# H6 register map
Vendor: Allwinner; Series: H6; File version: 0.1
CPU: CA53 0, little endian, MPU, no FPU, 0 interrupt priority bits
Registers are 32-bit, read-write, reset 0x0 unless marked. A register's access mark holds for its fields unless they carry their own. Offsets are from the block's base; [hi:lo] are bit positions; {n}, {i} and the like mark numbered series; 'fields as' and 'values as' point back to an identical list; <NAME> marks a mode.

## I2S/PCM0
Base 0x05090000
Same registers: I2S/PCM3(used_for_Audio_Codec) 0x0508F000, I2S/PCM1(used_for_HDMI) 0x05091000, I2S/PCM2 0x05092000
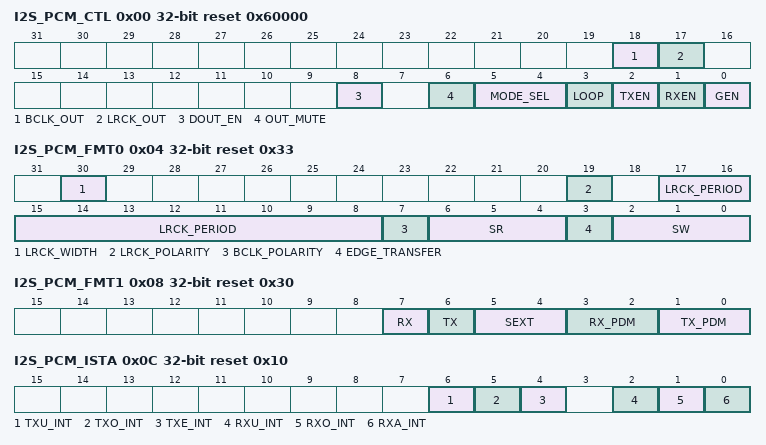
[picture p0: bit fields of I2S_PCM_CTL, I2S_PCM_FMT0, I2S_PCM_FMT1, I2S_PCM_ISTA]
0x00 I2S_PCM_CTL reset 0x60000
  [18] BCLK_OUT — 0: Input 1: Output
    0=Input; 1=Output
  [17] LRCK_OUT — 0: Input 1: Output
    0=Input; 1=Output
  [8] DOUT_EN — 0: Disable, Hi-Z State 1: Enable
    0=Disable, Hi-Z State; 1=Enable
  [6] OUT_MUTE — 0: Normal Transfer 1: Force DOUT to Output 0
    0=Normal Transfer; 1=Force DOUT to Output 0
  [5:4] MODE_SEL — Mode Selection 00: PCM Mode (offset 0: Long Frame; offset 1: Short Frame) 01: Left Mode (offset 0: LJ Mode; offset 1: I2S Mode) 10: Right-Justified Mode 11: Reserved
    0=PCM (PCM Mode (offset 0: Long Frame; offset 1: Short Frame)); 1=Left Mode (offset 0: LJ Mode; offset 1: I2S Mode); 2=Right-Justified Mode
  [3] LOOP — Loop Back Test 0: Normal Mode 1: Loop Back Test When Set `1` , Connecting the DOUT with the DIN.
    0=Normal Mode; 1=Loop Back Test When Set `1` , Connecting the DOUT with the DIN
  [2] TXEN — Transmitter Block Enable 0: Disable 1: Enable
    0=Disable; 1=Enable
  [1] RXEN — Receiver Block Enable 0: Disable 1: Enable
    0=Disable; 1=Enable
  [0] GEN — Globe Enable A disable on this bit overrides any other block or channel enables. 0: Disable 1: Enable
    0=Disable; 1=Enable
0x04 I2S_PCM_FMT0 reset 0x33
  [30] LRCK_WIDTH — (Only Apply in PCM Mode ) LRCK Width 0: LRCK = 1 BCLK Width (Short Frame) 1: LRCK = 2 BCLK Width (Long Frame)
    0=LRCK__equals__1 (LRCK = 1 BCLK Width (Short Frame)); 1=LRCK__equals__2 (LRCK = 2 BCLK Width (Long Frame))
  [19] LRCK_POLARITY — When Apply in I2S / Left-Justified / Right-Justified Mode: 0: Left Channel When LRCK is Low 1: Left Channel When LRCK is High When Apply in PCM Mode: 0: PCM LRCK Asserted at the Negative Edge 1: PCM LRCK Asserted at the Positive Edge
    0=Low (Left Channel When LRCK is Low); 1=High (Left Channel When LRCK is High When Apply in PCM Mode:); 0=PCM LRCK Asserted at the Negative Edge; 1=PCM LRCK Asserted at the Positive Edge
  [17:8] LRCK_PERIOD — It is used to program the number of BCLKs per channel of sample frame. This value is interpreted as follow: PCM Mode: Number of BCLKs within (Left + Right) channel width. I2S / Left-Justified / Right-Justified Mode: Number of BCLKs within each individual channel width (Left or Right) . N+1 For example: N = 7: 8 BCLKs width ... N = 1023: 1024 BCLKs width
  [7] BCLK_POLARITY — 0: Normal Mode, DOUT Drive Data at Negative Edge 1: Invert Mode, DOUT Drive Data at Positive Edge
    0=Normal Mode, DOUT Drive Data at Negative Edge; 1=Invert Mode, DOUT Drive Data at Positive Edge
  [6:4] SR — Sample Resolution 000: Reserved 001: 8-bit 010: 12-bit 011: 16-bit 100: 20-bit 101: 24-bit 110: 28-bit 111: 32-bit
    1=_8_bit; 2=_12_bit; 3=_16_bit; 4=_20_bit; 5=_24_bit; 6=_28_bit; 7=_32_bit
  [3] EDGE_TRANSFER — 0: DOUT Drive Data and DIN Sample Data at the Different BCLK Edge 1: DOUT Drive Data and DIN Sample Data at the Same BCLK Edge BCLK_POLARITY = 0, EDGE_TRANSFER = 0, DIN Sample Data at Positive Edge; BCLK_POLARITY = 0, EDGE_TRANSFER = 1, DIN Sample Data at Negative Edge; BCLK_POLARITY = 1, EDGE_TRANSFER = 0, DIN Sample Data at Negative Edge; BCLK_POLARITY = 1, EDGE_TRANSFER = 1, DIN Sample Data at Positive Edge.
    0=DOUT Drive Data and DIN Sample Data at the Different BCLK Edge; 1=DOUT Drive Data and DIN Sample Data at the Same BCLK Edge BCLK_POLARITY = 0, EDGE_TRANSFER = 0, DIN Sample Data at Positive Edge; BCLK_POLARITY = 0, EDGE_TRANSFER = 1, DIN Sample Data at Negative Edge; BCLK_POLARITY = 1, EDGE_TRANSFER = 0, DIN Sample Data at Negative Edge; BCLK_POLARITY = 1, EDGE_TRANSFER = 1, DIN Sample Data at Positive Edge
  [2:0] SW — Slot Width Select 000: Reserved 001: 8-bit 010: 12-bit 011: 16-bit 100: 20-bit 101: 24-bit 110: 28-bit 111: 32-bit
    values as SR
0x08 I2S_PCM_FMT1 reset 0x30
  [7] RX — MLS MSB/LSB First Select 0: MSB First 1: LSB First
    0=MSB (MSB First); 1=LSB (LSB First)
  [6] TX — MLS MSB/LSB First Select 0: MSB First 1: LSB First
    0=MSB (MSB First); 1=LSB (LSB First)
  [5:4] SEXT — Sign Extend in Slot [Sample Resolution < Slot Width] 00: Zeros or Audio Gain Padding at LSB Position 01: Sign Extension at MSB Position 10: Reserved 11: Transfer 0 after each Sample in each Slot
    0=Zeros or Audio Gain Padding at LSB Position; 1=Sign Extension at MSB Position; 3=Transfer 0 after each Sample in each Slot
  [3:2] RX_PDM — PCM Data Mode 00: Linear PCM 01: Reserved 10: 8-bit u-law 11: 8-bit A-law
    0=Linear_PCM; 2=_8_bit_ulaw; 3=_8_bit_Alaw
  [1:0] TX_PDM — PCM Data Mode 00: Linear PCM 01: Reserved 10: 8-bits u-law 11: 8-bits A-law
    0=Linear_PCM; 2=_8_bits_ulaw; 3=_8_bits_Alaw
0x0C I2S_PCM_ISTA reset 0x10
  [6] TXU_INT write-1-clears — TXFIFO Underrun Pending Interrupt 0: No Pending Interrupt 1: TXFIFO Underrun Pending Interrupt Write `1` to clear this interrupt.
    0=No Pending Interrupt; 1=TXFIFO (TXFIFO Underrun Pending Interrupt Write `1` to clear this interrupt.)
  [5] TXO_INT write-1-clears — TXFIFO Overrun Pending Interrupt 0: No Pending Interrupt 1: TXFIFO Overrun Pending Interrupt Write `1` to clear this interrupt.
    0=No Pending Interrupt; 1=TXFIFO (TXFIFO Overrun Pending Interrupt Write `1` to clear this interrupt.)
  [4] TXE_INT write-1-clears — TXFIFO Empty Pending Interrupt 0: No Pending IRQ 1: TXFIFO Empty Pending Interrupt When Data in TXFIFO are Less than TX Trigger Level Write `1` to clear this interrupt or automatic clear if interrupt condition fails.
    0=No Pending IRQ; 1=TXFIFO (TXFIFO Empty Pending Interrupt When Data in TXFIFO are Less than TX Trigger Level Write `1` to clear this interrupt or automatic clear if interrupt condition fails.)
  [2] RXU_INT write-1-clears — RXFIFO Underrun Pending Interrupt 0: No Pending Interrupt 1: RXFIFO Underrun Pending Interrupt Write `1` to clear this interrupt.
    0=No Pending Interrupt; 1=RXFIFO (RXFIFO Underrun Pending Interrupt Write `1` to clear this interrupt.)
  [1] RXO_INT write-1-clears — RXFIFO Overrun Pending Interrupt 0: No Pending IRQ 1: RXFIFO Overrun Pending IRQ Write `1` to clear this interrupt.
    0=No Pending IRQ; 1=RXFIFO (RXFIFO Overrun Pending IRQ Write `1` to clear this interrupt.)
  [0] RXA_INT write-1-clears — RXFIFO Data Available Pending Interrupt 0: No Pending IRQ 1: Data Available Pending IRQ When Data in RXFIFO are More than RX Trigger Level Write `1` to clear this interrupt or automatic clear if interrupt condition fails.
    0=No Pending IRQ; 1=Data Available Pending IRQ When Data in RXFIFO are More than RX Trigger Level Write `1` to clear this interrupt or automatic clear if interrupt condition fails
0x10 I2S_PCM_RXFIFO
  [31:0] RX_DATA ro — RX Sample Host can get one sample by reading this register. The left channel sample data is first and then the right channel sample.
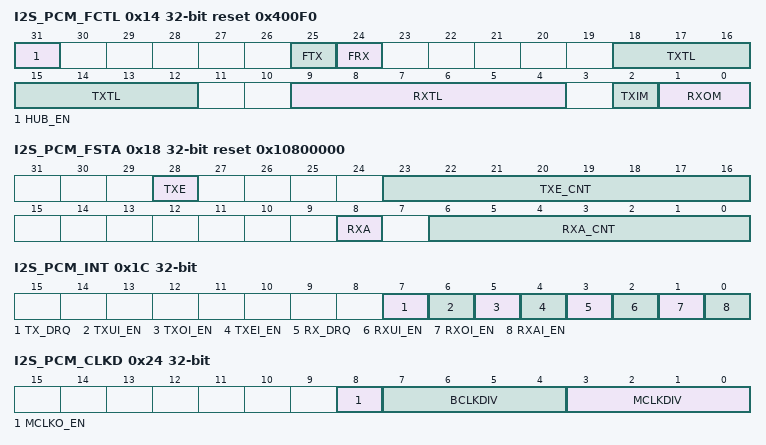
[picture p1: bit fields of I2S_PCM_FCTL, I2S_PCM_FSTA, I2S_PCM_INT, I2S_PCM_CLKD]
0x14 I2S_PCM_FCTL reset 0x400F0
  [31] HUB_EN — Audio Hub Enable 0 : Disable 1 : Enable
  [25] FTX write-1-clears — Write `1` to flush TXFIFO, self clear to `0`.
  [24] FRX write-1-clears — Write `1` to flush RXFIFO, self clear to `0`.
  [18:12] TXTL — TXFIFO Empty Trigger Level Interrupt and DMA request trigger level for TXFIFO normal condition. Trigger Level = TXTL
  [9:4] RXTL — RXFIFO Trigger Level Interrupt and DMA request trigger level for RXFIFO normal condition. Trigger Level = RXTL + 1
  [2] TXIM — TXFIFO Input Mode (Mode 0, 1) 0: Valid data at the MSB of TXFIFO register 1: Valid data at the LSB of TXFIFO register Example for 20-bit Transmitted Audio Sample: Mode 0: TXFIFO[31:0] = {APB_WDATA[31:12], 12`h0} Mode 1: TXFIFO[31:0] = {APB_WDATA[19:0], 12`h0}
    0=Valid data at the MSB of TXFIFO register; 1=Valid data at the LSB of TXFIFO register Example for 20-bit Transmitted Audio Sample: Mode 0: TXFIFO[31:0] = {APB_WDATA[31:12], 12`h0} Mode 1: TXFIFO[31:0] = {APB_WDATA[19:0], 12`h0}
  [1:0] RXOM — RXFIFO Output Mode (Mode 0, 1, 2, 3) 00: Expanding `0` at LSB of RXFIFO register 01: Expanding received sample sign bit at MSB of RXFIFO register 10: Truncating received samples at high half-word of RXFIFO register and low half-word of RXFIFO register is filled by `0` 11: Truncating received samples at low half-word of RXFIFO register and high half-word of RXFIFO register is expanded by its sign bit Example for 20-bit Received Audio Sample: Mode 0: APB_RDATA[31:0] = {RXFIFO[31:12], 12`h0} Mode 1: APB_RDATA[31:0] = {12{RXFIFO[31]}, RXFIFO[31:12]} Mode 2: APB_RDATA [31:0] = {RXFIFO[31:16], 16`h0} Mode 3: APB_RDATA[31:0] = {16{RXFIFO[31], RXFIFO[31:16]}
    0=Expanding `0` at LSB of RXFIFO register; 1=Expanding received sample sign bit at MSB of RXFIFO register; 2=Truncating received samples at high half-word of RXFIFO register and low half-word of RXFIFO register is filled by `0`; 3=Truncating received samples at low half-word of RXFIFO register and high half-word of RXFIFO register is expanded by its sign bit Example for 20-bit Received Audio Sample: Mode 0: APB_RDATA[31:0] = {RXFIFO[31:12], 12`h0} Mode 1: APB_RDATA[31:0] = {12{RXFIFO[31]}, RXFIFO[31:12]} Mode 2: APB_RDATA [31:0] = {RXFIFO[31:16], 16`h0} Mode 3: APB_RDATA[31:0] = {16{RXFIFO[31], RXFIFO[31:16]}
0x18 I2S_PCM_FSTA reset 0x10800000
  [28] TXE ro — TXFIFO Empty 0: No Room for New Sample in TXFIFO 1: More than One Room for New Sample in TXFIFO (>= 1 Word)
    0=No Room for New Sample in TXFIFO; 1=More than One Room for New Sample in TXFIFO (>= 1 Word)
  [23:16] TXE_CNT ro — TXFIFO Empty Space Word Counter
  [8] RXA ro — RXFIFO Available 0: No Available Data in RXFIFO 1: More than One Sample in RXFIFO (>= 1 Word)
    0=No Available Data in RXFIFO; 1=More than One Sample in RXFIFO (>= 1 Word)
  [6:0] RXA_CNT ro — RXFIFO Available Sample Word Counter
0x1C I2S_PCM_INT
  [7] TX_DRQ — TXFIFO Empty DRQ Enable 0: Disable 1: Enable
    0=Disable; 1=Enable
  [6] TXUI_EN — TXFIFO Underrun Interrupt Enable 0: Disable 1: Enable
    0=Disable; 1=Enable
  [5] TXOI_EN — TXFIFO Overrun Interrupt Enable 0: Disable 1: Enable When set to `1`, an interrupt happens when writing new audio data if TXFIFO is full.
    0=Disable; 1=Enable When set to `1`, an interrupt happens when writing new audio data if TXFIFO is full
  [4] TXEI_EN — TXFIFO Empty Interrupt Enable 0: Disable 1: Enable
    0=Disable; 1=Enable
  [3] RX_DRQ — RXFIFO Data Available DRQ Enable 0: Disable 1: Enable When set to `1`, RXFIFO DMA request line is asserted if data is available in RXFIFO.
    0=Disable; 1=Enable When set to `1`, RXFIFO DMA request line is asserted if data is available in RXFIFO
  [2] RXUI_EN — RXFIFO Underrun Interrupt Enable 0: Disable 1: Enable
    0=Disable; 1=Enable
  [1] RXOI_EN — RXFIFO Overrun Interrupt Enable 0: Disable 1: Enable
    0=Disable; 1=Enable
  [0] RXAI_EN — RXFIFO Data Available Interrupt Enable 0: Disable 1: Enable
    0=Disable; 1=Enable
0x20 I2S_PCM_TXFIFO
  [31:0] TX_DATA wo — TX Sample Transmitting left, right channel sample data should be written this register one by one. The left channel sample data is first and then the right channel sample.
0x24 I2S_PCM_CLKD
  [8] MCLKO_EN — 0: Disable MCLK Output 1: Enable MCLK Output NOTE Whether in Slave or Master mode, when this bit is set to , MCLK should be output.
    0=Disable MCLK Output; 1=Enable MCLK Output NOTE Whether in Slave or Master mode, when this bit is set to , MCLK should be output
  [7:4] BCLKDIV — BCLK Divide Ratio from PLL_AUDIO 0000: Reserved 0001: Divide by 1 0010: Divide by 2 0011: Divide by 4 0100: Divide by 6 0101: Divide by 8 0110: Divide by 12 0111: Divide by 16 1000: Divide by 24 1001: Divide by 32 1010: Divide by 48 1011: Divide by 64 1100: Divide by 96 1101: Divide by 128 1110: Divide by 176 1111: Divide by 192
    1=Divide_by_1; 2=Divide_by_2; 3=Divide_by_4; 4=Divide_by_6; 5=Divide_by_8; 6=Divide_by_12; 7=Divide_by_16; 8=Divide_by_24; 9=Divide_by_32; 10=Divide_by_48; 11=Divide_by_64; 12=Divide_by_96; 13=Divide_by_128; 14=Divide_by_176; 15=Divide_by_192
  [3:0] MCLKDIV — MCLK Divide Ratio from PLL_AUDIO 0000: Reserved 0001: Divide by 1 0010: Divide by 2 0011: Divide by 4 0100: Divide by 6 0101: Divide by 8 0110: Divide by 12 0111: Divide by 16 1000: Divide by 24 1001: Divide by 32 1010: Divide by 48 1011: Divide by 64 1100: Divide by 96 1101: Divide by 128 1110: Divide by 176 1111: Divide by 192
    values as BCLKDIV
0x28 I2S_PCM_TXCNT
  [31:0] TX_CNT — TX Sample Counter The audio sample number of sending into TXFIFO. When one sample is put into TXFIFO by DMA or by host IO, the TX sample counter register increases by one. The TX sample counter register can be set to any initial value at any time. After been updated by the initial value, the counter register should count on base of this initial value.
0x2C I2S_PCM_RXCNT
  [31:0] RX_CNT — RX Sample Counter The audio sample number of writing into RXFIFO. When one sample is written by Digital Audio Engine, the RX sample counter register increases by one. The RX sample counter register can be set to any initial value at any time. After been updated by the initial value, the counter register should count on base of this initial value.
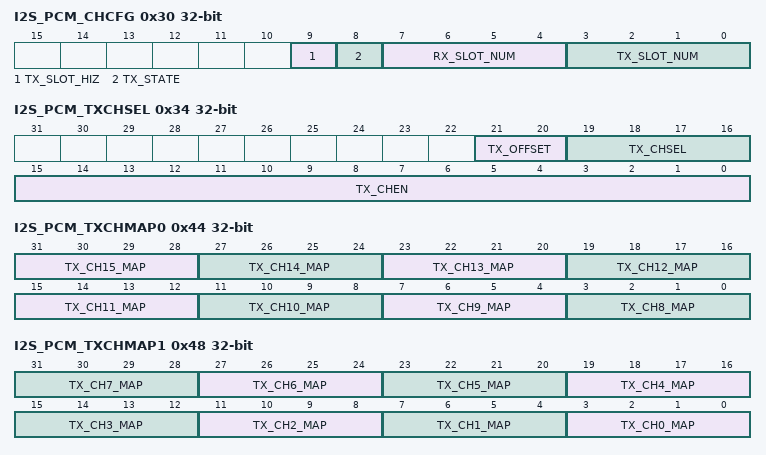
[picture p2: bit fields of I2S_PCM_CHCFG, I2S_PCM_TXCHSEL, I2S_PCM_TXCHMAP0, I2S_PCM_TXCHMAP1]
0x30 I2S_PCM_CHCFG
  [9] TX_SLOT_HIZ — 0: Normal mode for the last half cycle of BCLK in the Slot 1: Turn to Hi-Z State for the last half cycle of BCLK in the Slot
    0=Normal mode for the last half cycle of BCLK in the Slot; 1=Turn to Hi-Z State for the last half cycle of BCLK in the Slot
  [8] TX_STATE — 0: Transfer level 0 When Not Transferring Slot 1: Turn to Hi-Z State (TDM) When Not Transferring Slot
    0=Transfer level 0 When Not Transferring Slot; 1=Turn to Hi-Z State (TDM) When Not Transferring Slot
  [7:4] RX_SLOT_NUM — RX Channel/Slot number between CPU/DMA and RXFIFO 0000: 1 Channel or Slot ... 0111: 8 Channels or Slots 1000: 9 Channels or Slots ... 1111:16 Channels or Slots
    0=1 Channel or Slot ; 7=8 Channels or Slots; 8=9 Channels or Slots ... 1111:16 Channels or Slots
  [3:0] TX_SLOT_NUM — TX Channel/Slot number between CPU/DMA and TXFIFO 0000: 1 Channel or Slot ... 0111: 8 Channels or Slots 1000: 9 Channels or Slots ... 1111:16 Channels or Slots
    values as RX_SLOT_NUM
0x34 I2S_PCM_TXCHSEL
  [21:20] TX_OFFSET — TX offset Tune, TX Data offset to LRCK 0: No offset n: Data is offset by n BCLKs to LRCK
  [19:16] TX_CHSEL — TX Channel (Slot) number select for each output 0000: 1 Channel / Slot ... 0111: 8 Channels / Slots 1000: 9 Channels / Slots ... 1111: 16 Channels / Slots
    0=1 Channel / Slot ; 7=8 Channels / Slots; 8=9 Channels / Slots ; 15=16 Channels / Slots
  [15:0] TX_CHEN — TX Channel (Slot) Enable, bit[15:0] refer to Slot [15:0]. When one or more Slot(s) is(are) disabled, the affected Slot(s) is(are) set to the disable state. 0: Disable 1: Enable
0x44 I2S_PCM_TXCHMAP0
  [31:28] TX_CH15_MAP — TX Channel 15 Mapping 0000: 1st Sample ... 0111: 8th Sample 1000: 9th Sample ... 1111: 16th Sample
    0=1st Sample ; 7=8th Sample; 8=9th Sample ; 15=16th Sample
  [27:24] TX_CH14_MAP — TX Channel 14 Mapping 0000: 1st Sample ... 0111: 8th Sample 1000: 9th Sample ... 1111: 16th sample
    0=1st Sample ; 7=8th Sample; 8=9th Sample ; 15=_16th_sample
  [23:20] TX_CH13_MAP — TX Channel 13 Mapping 0000: 1st Sample ... 0111: 8th Sample 1000: 9th Sample ... 1111: 16th Sample
    0=1st Sample ; 7=8th Sample; 8=9th Sample ; 15=16th Sample
  [19:16] TX_CH12_MAP — TX Channel 12 Mapping 0000: 1st Sample ... 0111: 8th Sample 1000: 9th Sample ... 1111: 16th Sample
    0=1st Sample ; 7=8th Sample; 8=9th Sample ; 15=16th Sample
  [15:12] TX_CH11_MAP — TX Channel 11 Mapping 0000: 1st Sample ... 0111: 8th Sample 1000: 9th Sample ... 1111: 16th sample
    0=1st Sample ; 7=8th Sample; 8=9th Sample ; 15=_16th_sample
  [11:8] TX_CH10_MAP — TX Channel 10 Mapping 0000: 1st Sample ... 0111: 8th Sample 1000: 9th Sample ... 1111: 16th Sample
    0=1st Sample ; 7=8th Sample; 8=9th Sample ; 15=16th Sample
  [7:4] TX_CH9_MAP — TX Channel 9 Mapping 0000: 1st Sample ... 0111: 8th Sample 1000: 9th Sample ... 1111: 16th Sample
    0=1st Sample ; 7=8th Sample; 8=9th Sample ; 15=16th Sample
  [3:0] TX_CH8_MAP — TX Channel 8 Mapping 0000: 1st Sample ... 0111: 8th Sample 1000: 9th Sample ... 1111: 16th Sample
    0=1st Sample ; 7=8th Sample; 8=9th Sample ; 15=16th Sample
0x48 I2S_PCM_TXCHMAP1
  [all] fields
    0=1st Sample ; 7=8th Sample; 8=9th Sample ; 15=16th Sample
  [4n+3:4n] TX_CH{n}_MAP (n=0..7) — TX Channel {n} Mapping 0000: 1st Sample ... 0111: 8th Sample 1000: 9th Sample ... 1111: 16th Sample
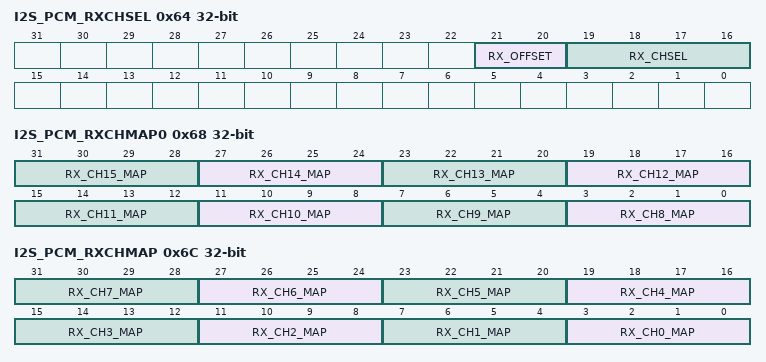
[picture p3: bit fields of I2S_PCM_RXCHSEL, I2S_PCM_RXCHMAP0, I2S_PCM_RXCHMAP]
0x64 I2S_PCM_RXCHSEL
  [21:20] RX_OFFSET — RX offset Tune, RX Data offset to LRCK 0: No offset n: Data is offset by n BCLKs to LRCK
  [19:16] RX_CHSEL — RX Channel (Slot) Number Select for Input 0000: 1 Channel / Slot ... 0111: 8 Channels / Slots 1000: 9 Channels / Slots ... 1111: 16 Channels / Slots
    values as I2S_PCM_TXCHSEL.TX_CHSEL
0x68 I2S_PCM_RXCHMAP0
  [all] fields
    0=1st Sample ; 7=8th Sample; 8=9th Sample ; 15=16th Sample
  [4n-29:4n-32] RX_CH{n}_MAP (n=8..15) — RX Channel {n} Mapping 0000: 1st Sample ... 0111: 8th Sample 1000: 9th Sample ... 1111: 16th Sample
0x6C I2S_PCM_RXCHMAP
  [all] fields
    0=1st Sample ; 7=8th Sample; 8=9th Sample ; 15=16th Sample
  [4n+3:4n] RX_CH{n}_MAP (n=0..7) — RX Channel {n} Mapping 0000: 1st Sample ... 0111: 8th Sample 1000: 9th Sample ... 1111: 16th Sample
